# STM32H553xx register map
File version: 1.0
Registers are 32-bit, read-write, reset 0x0 unless marked. A register's access mark holds for its fields unless they carry their own. Offsets are from the block's base; [hi:lo] are bit positions; {n}, {i} and the like mark numbered series; 'fields as' and 'values as' point back to an identical list.

## GTZC_TZSC1 — Global TrustZone Controller
Base 0x40032400
Same registers: GTZC_TZSC1_S 0x50032400
0x00 CR — TZSC control register
  [0] LCK
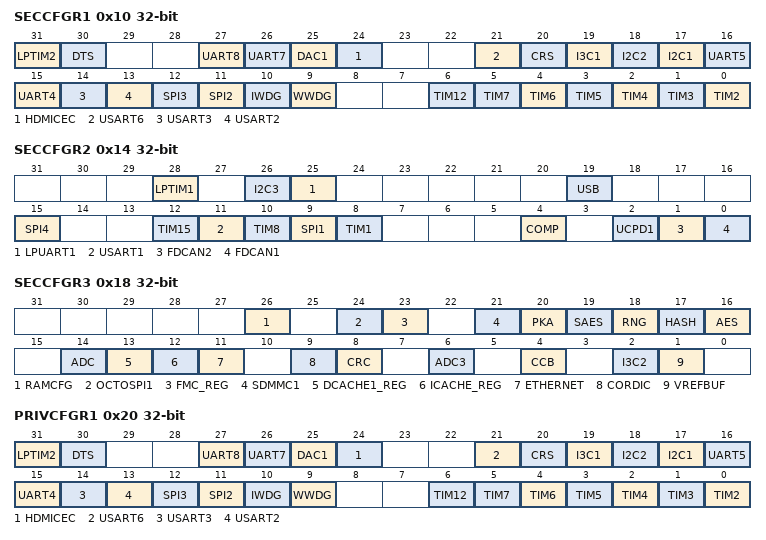
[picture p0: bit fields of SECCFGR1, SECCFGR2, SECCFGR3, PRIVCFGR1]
0x10 SECCFGR1 — TZSC secure configuration register 1
  [31] LPTIM2, [30] DTS, [27] UART8, [26] UART7, [25] DAC1, [24] HDMICEC, [21] USART6, [20] CRS, [19] I3C1, [18] I2C2, [17] I2C1, [16] UART5, [15] UART4, [14] USART3, [13] USART2, [12] SPI3, [11] SPI2, [10] IWDG, [9] WWDG, [6] TIM12, [n-2] TIM{n} (n=2..7)
0x14 SECCFGR2 — TZSC secure configuration register 2
  [28] LPTIM1, [26] I2C3, [25] LPUART1, [19] USB, [15] SPI4, [12] TIM15, [11] USART1, [10] TIM8, [9] SPI1, [8] TIM1, [4] COMP, [2] UCPD1, [1] FDCAN2, [0] FDCAN1
0x18 SECCFGR3 — TZSC secure configuration register 3
  [26] RAMCFG, [24] OCTOSPI1, [23] FMC_REG, [21] SDMMC1, [20] PKA, [19] SAES, [18] RNG, [17] HASH, [16] AES, [14] ADC, [13] DCACHE1_REG, [12] ICACHE_REG, [11] ETHERNET, [9] CORDIC, [8] CRC, [6] ADC3, [4] CCB, [2] I3C2, [1] VREFBUF
0x20 PRIVCFGR1 — TZSC privilege configuration register 1
  fields as SECCFGR1
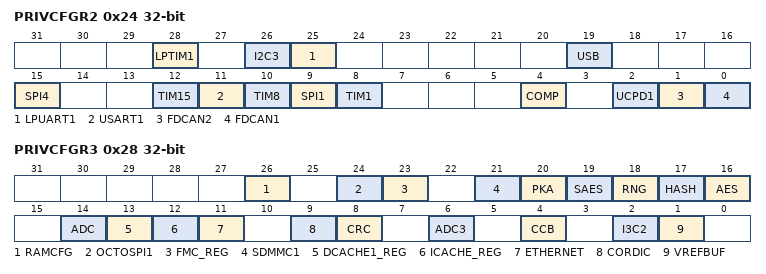
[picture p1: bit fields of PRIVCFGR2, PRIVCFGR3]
0x24 PRIVCFGR2 — TZSC privilege configuration register 2
  fields as SECCFGR2
0x28 PRIVCFGR3 — TZSC privilege configuration register 3
  fields as SECCFGR3
{0x30+0x10*i} MPCWM{i}ACFGR (i=1..4) — TZSC memory {i} sub-region A watermark configuration register
{0x34+0x10*i} MPCWM{i}AR (i=1..4) — TZSC memory {i} sub-region A watermark register
{0x38+0x10*i} MPCWM{i}BCFGR (i=1..4) — TZSC memory {i} sub-region B watermark configuration register
{0x3C+0x10*i} MPCWM{i}BR (i=1..4) — TZSC memory {i} sub-region B watermark register

## GTZC_TZIC1
Base 0x40032800
Same registers: GTZC_TZIC1_S 0x50032800
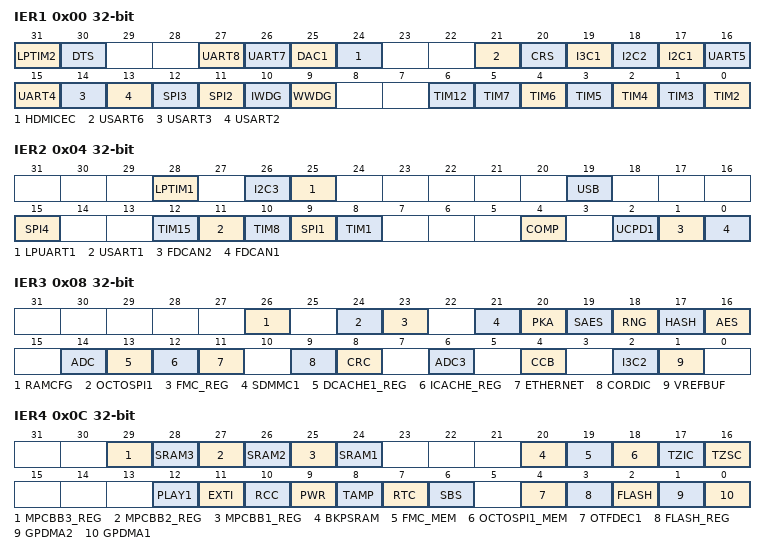
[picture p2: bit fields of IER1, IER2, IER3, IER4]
0x00 IER1 — TZIC interrupt enable register 1
  [31] LPTIM2, [30] DTS, [27] UART8, [26] UART7, [25] DAC1, [24] HDMICEC, [21] USART6, [20] CRS, [19] I3C1, [18] I2C2, [17] I2C1, [16] UART5, [15] UART4, [14] USART3, [13] USART2, [12] SPI3, [11] SPI2, [10] IWDG, [9] WWDG, [6] TIM12, [n-2] TIM{n} (n=2..7)
0x04 IER2 — TZIC interrupt enable register 2
  [28] LPTIM1, [26] I2C3, [25] LPUART1, [19] USB, [15] SPI4, [12] TIM15, [11] USART1, [10] TIM8, [9] SPI1, [8] TIM1, [4] COMP, [2] UCPD1, [1] FDCAN2, [0] FDCAN1
0x08 IER3 — TZIC interrupt enable register 3
  [26] RAMCFG, [24] OCTOSPI1, [23] FMC_REG, [21] SDMMC1, [20] PKA, [19] SAES, [18] RNG, [17] HASH, [16] AES, [14] ADC, [13] DCACHE1_REG, [12] ICACHE_REG, [11] ETHERNET, [9] CORDIC, [8] CRC, [6] ADC3, [4] CCB, [2] I3C2, [1] VREFBUF
0x0C IER4 — TZIC interrupt enable register 4
  [29] MPCBB3_REG, [28] SRAM3, [27] MPCBB2_REG, [26] SRAM2, [25] MPCBB1_REG, [24] SRAM1, [20] BKPSRAM, [19] FMC_MEM, [18] OCTOSPI1_MEM, [17] TZIC, [16] TZSC, [12] PLAY1, [11] EXTI, [10] RCC, [9] PWR, [8] TAMP, [7] RTC, [6] SBS, [4] OTFDEC1, [3] FLASH_REG, [2] FLASH, [1] GPDMA2, [0] GPDMA1
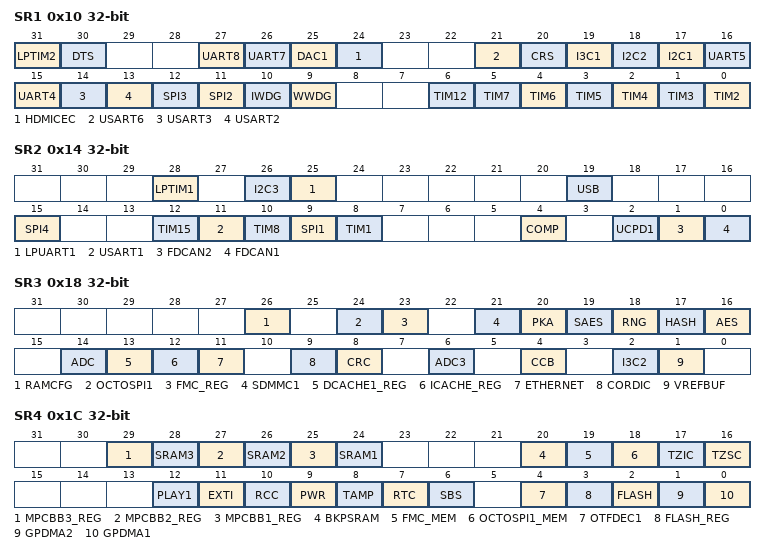
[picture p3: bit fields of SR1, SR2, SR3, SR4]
0x10 SR1 — TZIC status register 1
  fields as IER1
0x14 SR2 — TZIC status register 2
  fields as IER2
0x18 SR3 — TZIC status register 3
  fields as IER3
0x1C SR4 — TZIC status register 4
  fields as IER4
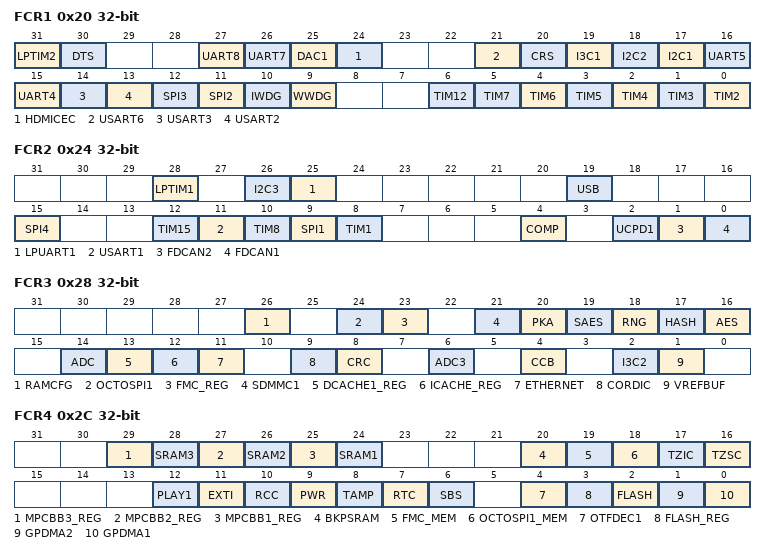
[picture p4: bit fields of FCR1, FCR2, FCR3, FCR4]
0x20 FCR1 — TZIC flag clear register 1
  fields as IER1
0x24 FCR2 — TZIC flag clear register 2
  fields as IER2
0x28 FCR3 — TZIC flag clear register 3
  fields as IER3
0x2C FCR4 — TZIC flag clear register 3
  fields as IER4

## GTZC_MPCBB1
Base 0x40032C00
Same registers: GTZC_MPCBB2 0x40033000, GTZC_MPCBB3 0x40033400, GTZC_MPCBB1_S 0x50032C00, GTZC_MPCBB2_S 0x50033000, GTZC_MPCBB3_S 0x50033400
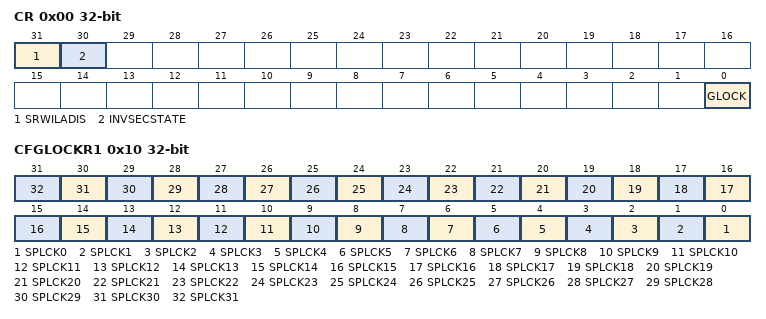
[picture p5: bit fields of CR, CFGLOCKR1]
0x00 CR — MPCBBx control register
  [31] SRWILADIS, [30] INVSECSTATE, [0] GLOCK
0x10 CFGLOCKR1 — MPCBBx lock register
  [n] SPLCK{n} (n=0..31)
{0x100+4i} SECCFGR{i} (i=0..31) — MPCBBx security configuration registers
{0x200+4i} PRIVCFGR{i} (i=0..31) — MPCBBx privilege configuration registers

## GPIOA — General Purpose I/O
Base 0x42020000
Same registers: GPIOB 0x42020400, GPIOC 0x42020800, GPIOD 0x42020C00, GPIOE 0x42021000, GPIOF 0x42021400, GPIOG 0x42021800, GPIOH 0x42021C00, GPIOA_S 0x52020000, GPIOB_S 0x52020400, GPIOC_S 0x52020800, GPIOD_S 0x52020C00, GPIOE_S 0x52021000, GPIOF_S 0x52021400, GPIOG_S 0x52021800, GPIOH_S 0x52021C00
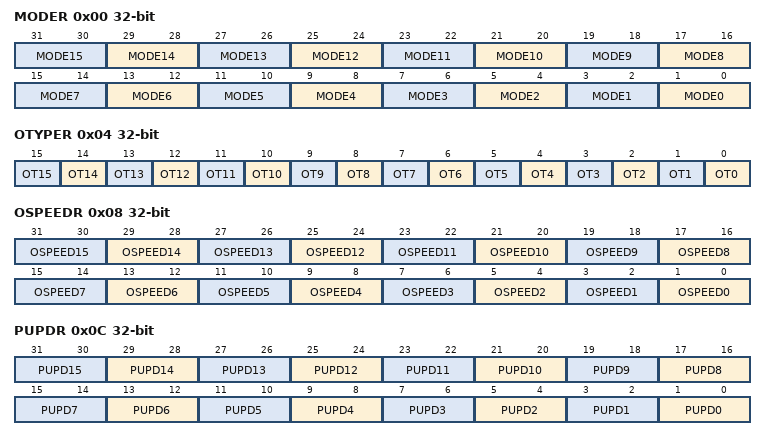
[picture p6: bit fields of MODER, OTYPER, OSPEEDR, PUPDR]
0x00 MODER — GPIO port mode register
  [2n+1:2n] MODE{n} (n=0..15)
0x04 OTYPER — GPIO port output type register
  [n] OT{n} (n=0..15)
0x08 OSPEEDR — GPIO port output speed register
  [2n+1:2n] OSPEED{n} (n=0..15)
0x0C PUPDR — GPIO port pull-up/pull-down register
  [2n+1:2n] PUPD{n} (n=0..15)
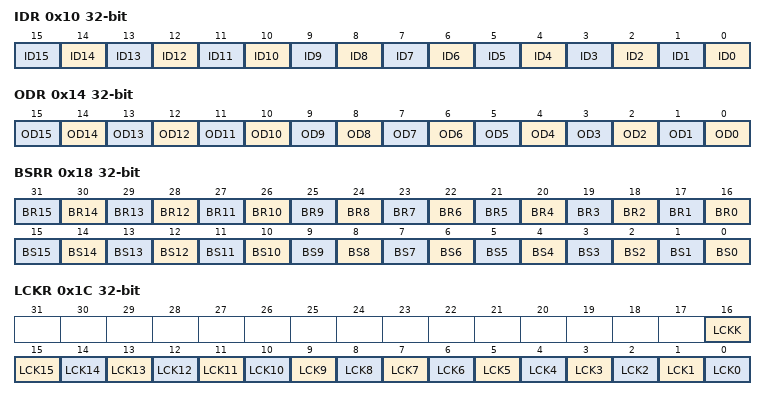
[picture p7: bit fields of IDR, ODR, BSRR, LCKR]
0x10 IDR — GPIO port input data register
  [n] ID{n} (n=0..15)
0x14 ODR — GPIO port output data register
  [n] OD{n} (n=0..15)
0x18 BSRR — GPIO port bit set/reset register
  [n+16] BR{n} (n=0..15), [n] BS{n} (n=0..15)
0x1C LCKR — GPIO port configuration lock register
  [16] LCKK, [n] LCK{n} (n=0..15)
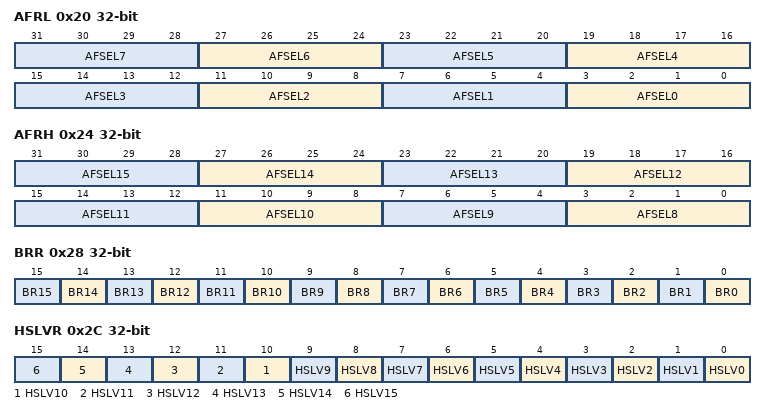
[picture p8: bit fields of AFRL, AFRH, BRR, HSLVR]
0x20 AFRL — GPIO alternate function registers
  [4n+3:4n] AFSEL{n} (n=0..7)
0x24 AFRH — GPIO alternate function registers
  [4n-29:4n-32] AFSEL{n} (n=8..15)
0x28 BRR — GPIO Bit Reset register
  [n] BR{n} (n=0..15)
0x2C HSLVR — GPIO high-speed low voltage register
  [n] HSLV{n} (n=0..15)
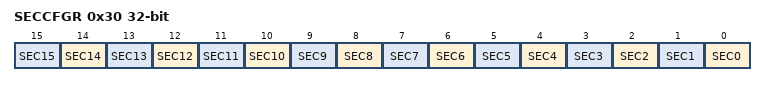
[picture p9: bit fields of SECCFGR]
0x30 SECCFGR — GPIO secure configuration register
  [n] SEC{n} (n=0..15)
